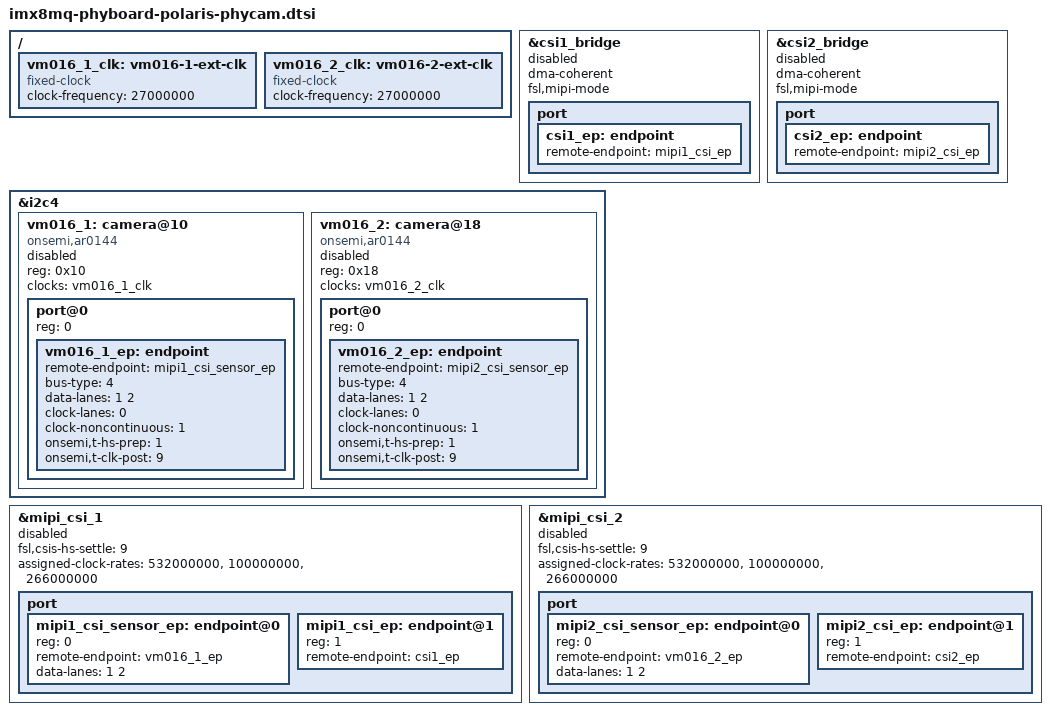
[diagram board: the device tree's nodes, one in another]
// SPDX-License-Identifier: GPL-2.0
/*
 * Copyright (C) 2021 PHYTEC Messtechnik GmbH
 * Author: Stefan Riedmueller <s.riedmueller@phytec.de>
 */

/ {
	vm016_1_clk: vm016-1-ext-clk {
		#clock-cells = <0>;
		compatible = "fixed-clock";
		clock-frequency = <27000000>;
	};

	vm016_2_clk: vm016-2-ext-clk {
		#clock-cells = <0>;
		compatible = "fixed-clock";
		clock-frequency = <27000000>;
	};
};

&csi1_bridge {
	dma-coherent;
	fsl,mipi-mode;
	status = "disabled";

	port {
		csi1_ep: endpoint {
			remote-endpoint = <&mipi1_csi_ep>;
		};
	};
};

&csi2_bridge {
	dma-coherent;
	fsl,mipi-mode;
	status = "disabled";

	port {
		csi2_ep: endpoint {
			remote-endpoint = <&mipi2_csi_ep>;
		};
	};
};

&i2c4 {
	vm016_1: camera@10 {
		#address-cells = <1>;
		#size-cells = <0>;

		compatible = "onsemi,ar0144";
		reg = <0x10>;
		clock-names = "ext";
		clocks = <&vm016_1_clk>;

		status = "disabled";

		port@0 {
			reg = <0>;

			vm016_1_ep: endpoint {
				remote-endpoint = <&mipi1_csi_sensor_ep>;
				bus-type = <4>; /* MIPI CSI-2 D-PHY */
				data-lanes = <1 2>;
				clock-lanes = <0>;
				clock-noncontinuous = <1>;
				onsemi,t-hs-prep = <1>;
				onsemi,t-clk-post = <9>;
			};
		};
	};

	vm016_2: camera@18 {
		#address-cells = <1>;
		#size-cells = <0>;

		compatible = "onsemi,ar0144";
		reg = <0x18>;
		clock-names = "ext";
		clocks = <&vm016_2_clk>;

		status = "disabled";

		port@0 {
			reg = <0>;

			vm016_2_ep: endpoint {
				remote-endpoint = <&mipi2_csi_sensor_ep>;
				bus-type = <4>; /* MIPI CSI-2 D-PHY */
				data-lanes = <1 2>;
				clock-lanes = <0>;
				clock-noncontinuous = <1>;
				onsemi,t-hs-prep = <1>;
				onsemi,t-clk-post = <9>;
			};
		};
	};
};

&mipi_csi_1 {
	fsl,csis-hs-settle = <9>;
	assigned-clock-rates = <532000000>, <100000000>, <266000000>;
	status = "disabled";

	port {
		#address-cells = <1>;
		#size-cells = <0>;

		mipi1_csi_sensor_ep: endpoint@0 {
			reg = <0>;
			remote-endpoint = <&vm016_1_ep>;
			data-lanes = <1 2>;
		};

		mipi1_csi_ep: endpoint@1 {
			reg = <1>;
			remote-endpoint = <&csi1_ep>;
		};
	};
};

&mipi_csi_2 {
	fsl,csis-hs-settle = <9>;
	assigned-clock-rates = <532000000>, <100000000>, <266000000>;
	status = "disabled";

	port {
		#address-cells = <1>;
		#size-cells = <0>;

		mipi2_csi_sensor_ep: endpoint@0 {
			reg = <0>;
			remote-endpoint = <&vm016_2_ep>;
			data-lanes = <1 2>;
		};

		mipi2_csi_ep: endpoint@1 {
			reg = <1>;
			remote-endpoint = <&csi2_ep>;
		};
	};
};
